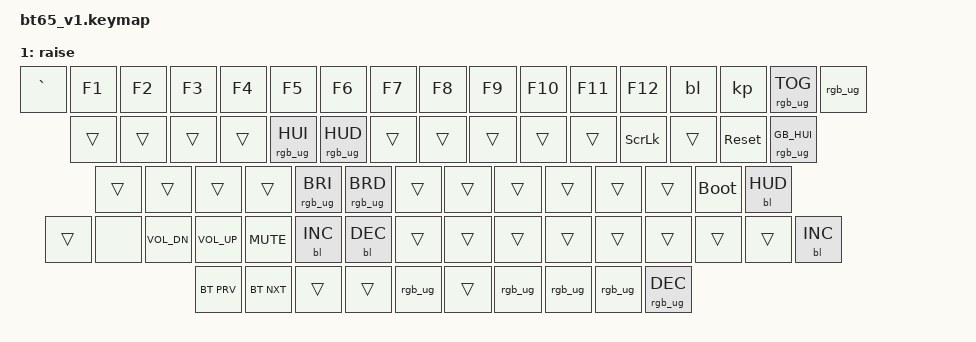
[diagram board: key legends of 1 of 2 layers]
#include <behaviors.dtsi>
#include <dt-bindings/zmk/keys.h>
#include <dt-bindings/zmk/bt.h>
#include <dt-bindings/zmk/rgb.h>
#include <dt-bindings/zmk/backlight.h>

#define ANSI
//#define ISO
//#define HHKB

/ {
  chosen {
  #ifdef ANSI
    zmk,matrix_transform = &ansi_transform;
  #elif defined(ISO)
    zmk,matrix_transform = &iso_transform;
  #elif defined(HHKB)
    zmk,matrix_transform = &hhkb_transform;
  #else
  #error "Layout not defined, please define a layout by uncommenting the appropriate line in bt65_v1.keymap"
  #endif
  };

  keymap {
    compatible = "zmk,keymap";
    #ifdef ANSI
    default_layer {
        // ------------------------------------------------------------------------------------------------
        // | ESC |  1  |  2  |  3  |  4  |  5  |  6  |  7  |  8  |  9  |  0  |  -  |  =  |   BKSP   | DEL |
        // | TAB   |  Q  |  W  |  E  |  R  |  T  |  Y  |  U  |  I  |  O  |  P  |  [  |  ]  |   \    | INS |
        // | CAPS   |  A  |  S  |  D  |  F  |  G  |  H  |  J  |  K  |  L  |  ;  |  '  |    ENTER    | PGUP|
        // |  SHIFT   |  Z  |  X  |  C  |  V  |  B  |  N  |  M  |  ,  |  .  |  /  |   SHIFT   | UP  | PGDN|
        // |  CTL  |  WIN  |  ALT  |             SPACE                | ALT |  1  |RCTRL| LEFT| DOWN|RIGHT|
        // ------------------------------------------------------------------------------------------------
      bindings = <

        &kp ESC &kp N1 &kp N2 &kp N3 &kp N4 &kp N5 &kp N6 &kp N7 &kp  N8   &kp  N9   &kp N0 &kp MINUS &kp EQUAL &kp BKSP &kp DEL
        &kp TAB   &kp Q  &kp W  &kp E  &kp R  &kp T  &kp Y  &kp U  &kp  I    &kp  O  &kp  P   &kp LBKT &kp RBKT &kp BSLH &kp INS
        &kp CLCK   &kp A  &kp S  &kp D  &kp F  &kp G  &kp H  &kp J  &kp  K    &kp  L  &kp SEMI &kp SQT         &kp RET &kp PG_UP
        &kp LSHFT     &kp Z  &kp X  &kp C  &kp V  &kp B  &kp N  &kp M  &kp COMMA &kp DOT &kp FSLH   &kp RSHFT   &kp UP &kp PG_DN
        &kp LCTRL &kp LGUI &kp LALT            &kp SPACE                   &kp RALT  &mo 1 &kp RCTRL &kp LEFT &kp DOWN &kp RIGHT
      >;
      sensor-bindings = <&inc_dec_kp C_VOL_UP C_VOL_DN>;
    };
    raise {
        // --------------------------------------------------------------------------------------------------
        // |GRAVE| F1  | F2  | F3  | F4  | F5  | F6  | F7  | F8  | F9  | F10 | F11 | F12 |PRSCRN|RGB_TOG|RGB_TOG|
        // | TAB  |  Q  |  W  |  E  | HUI | HUD |  Y  |  U  |  I  |  O  |  P  | SLCK|  ]  |  RESET   | RGB_HUI|
        // | CAPS  |  A  |  S  |  D  | BRI | BRD |  H  |  J  |  K  |  L  |  ;  |  '  |      BOOT     | RGB_HUD|
        // |SHIFT| NONE|VOLDN|VOLUP| MUTE|BLINC|BLDEC|  N  |  M  |  ,  |  .  |  /  |SHIFT| NONE|  UP | BL_INC|
        // | BT_PRV| BT_NXT|  ALT  |            SPACE                 | RGB_BRI |  1  | RGB_SPD| RGB_EFF| RGB_SAD |BL_DEC|
        // --------------------------------------------------------------------------------------------------
      bindings = <
        &kp GRAVE &kp F1 &kp F2 &kp F3 &kp F4 &kp F5 &kp F6 &kp F7 &kp F8 &kp F9 &kp F10 &kp F11 &kp F12 &bl &kp &rgb_ug RGB_TOG &rgb_ug
        &trans &trans &trans &trans &rgb_ug RGB_HUI &rgb_ug RGB_HUD &trans &trans &trans &trans &trans &kp SLCK &trans  &sys_reset  &rgb_ug GB_HUI
        &trans   &trans &trans &trans &rgb_ug RGB_BRI &rgb_ug RGB_BRD &trans &trans &trans &trans &trans  &trans  &bootloader &bl RGB_HUD
        &trans &none &kp C_VOL_DN &kp C_VOL_UP &kp C_MUTE &bl BL_INC &bl BL_DEC &trans &trans &trans &trans &trans &trans  &trans &trans &bl BL_INC
        &bt BT_PRV &bt BT_NXT  &trans              &trans                            &rgb_ug  &trans   &rgb_ug &rgb_ug &rgb_ug &rgb_ug BL_DEC
      >;
      sensor-bindings = <&inc_dec_kp C_VOL_UP C_VOL_DN>;
    };
    #elif defined(ISO)
    default_layer {
        // ------------------------------------------------------------------------------------------------
        // | ESC |  1  |  2  |  3  |  4  |  5  |  6  |  7  |  8  |  9  |  0  |  -  |  =  |   BKSP   | DEL |
        // | TAB   |  Q  |  W  |  E  |  R  |  T  |  Y  |  U  |  I  |  O  |  P  |  [  |  ]  |        | INS |
        // | CAPS   |  A  |  S  |  D  |  F  |  G  |  H  |  J  |  K  |  L  |  ;  |  '  |  #  | ENTER | PGUP|
        // |SHIFT |  \  |  Z  |  X  |  C  |  V  |  B  |  N  |  M  |  ,  |  .  |  /  |  SHIFT  | UP  | PGDN|
        // |  CTL  |  WIN  |  ALT  |             SPACE                | ALT |  1  |RCTRL| LEFT| DOWN|RIGHT|
        // ------------------------------------------------------------------------------------------------
      bindings = <

        &kp ESC &kp N1 &kp N2 &kp N3 &kp N4 &kp N5 &kp N6 &kp N7 &kp  N8   &kp  N9   &kp N0 &kp MINUS &kp EQUAL &kp BKSP &kp DEL
        &kp TAB   &kp Q  &kp W  &kp E  &kp R  &kp T  &kp Y  &kp U  &kp  I    &kp  O  &kp  P   &kp LBKT &kp RBKT          &kp INS
        &kp CLCK   &kp A  &kp S  &kp D  &kp F  &kp G  &kp H  &kp J  &kp  K    &kp  L  &kp SEMI &kp SQT &kp NON_US_HASH &kp RET &kp PG_UP
        &kp LSHFT &kp NON_US_BSLH &kp Z  &kp X  &kp C  &kp V  &kp B  &kp N  &kp M  &kp COMMA &kp DOT &kp FSLH   &kp RSHFT   &kp UP &kp PG_DN
        &kp LCTRL &kp LGUI &kp LALT            &kp SPACE                   &kp RALT  &mo 1 &kp RCTRL &kp LEFT &kp DOWN &kp RIGHT
      >;
      sensor-bindings = <&inc_dec_kp C_VOL_UP C_VOL_DN>;
    };
    raise {
        // --------------------------------------------------------------------------------------------------
        // |GRAVE| F1  | F2  | F3  | F4  | F5  | F6  | F7  | F8  | F9  | F10 | F11 | F12 |  BL_TOG  |RGB_TOG|
        // | TAB  |  Q  |  W  |  E  | HUI | HUD |  Y  |  U  |  I  |  O  |  P  | SLCK|  ]  |          | PSCRN|
        // | CAPS  |  A  |  S  |  D  | BRI | BRD |  H  |  J  |  K  |  L  |  ;  |  '  |RESET|   BOOT  | P_BRK|
        // |SHIFT |VOLDN|VOLUP| MUTE|BLINC|BLDEC|  B  |  N  |  M  |  ,  |  .  |  /  |  SHIFT  | HOME |  END |
        // | BT_PRV| BT_NXT|  ALT  |            SPACE               | ALT |  1  | CTRL | LEFT | DOWN |BT_CLR|
        // --------------------------------------------------------------------------------------------------
      bindings = <
        &kp GRAVE &kp F1 &kp F2 &kp F3 &kp F4 &kp F5 &kp F6 &kp F7 &kp F8 &kp F9 &kp F10 &kp F11 &kp F12 &bl BL_TOG &rgb_ug RGB_TOG
        &trans &trans &trans &trans &rgb_ug RGB_HUI &rgb_ug RGB_HUD &trans &trans &trans &trans &trans &kp SLCK &trans &kp PSCRN
        &trans   &trans &trans &trans &rgb_ug RGB_BRI &rgb_ug RGB_BRD &trans &trans &trans &trans &trans  &trans  &sys_reset  &bootloader &kp PAUSE_BREAK
        &trans &kp C_VOL_DN &kp C_VOL_UP &kp C_MUTE &bl BL_INC &bl BL_DEC  &trans &trans &trans &trans &trans &trans &trans  &kp HOME &kp END
        &bt BT_PRV &bt BT_NXT  &trans              &trans                            &trans   &trans   &trans &trans &trans  &bt BT_CLR
      >;
      sensor-bindings = <&inc_dec_kp C_VOL_UP C_VOL_DN>;
    };
    #elif defined(HHKB)
    default_layer {
        // ------------------------------------------------------------------------------------------------
        // | ESC |  1  |  2  |  3  |  4  |  5  |  6  |  7  |  8  |  9  |  0  |  -  |  =  |   BKSP   | DEL |
        // | TAB   |  Q  |  W  |  E  |  R  |  T  |  Y  |  U  |  I  |  O  |  P  |  [  |  ]  |   \    | HOME|
        // | CAPS   |  A  |  S  |  D  |  F  |  G  |  H  |  J  |  K  |  L  |  ;  |  '  |    ENTER    | END |
        // |  SHIFT   |  Z  |  X  |  C  |  V  |  B  |  N  |  M  |  ,  |  .  |  /  |      SHIFT      | PGUP|
        // |  CTL  |  WIN  |  ALT  |               SPACE                   |  ALT  |   1   |  CTRL  | PGDN|
        // ------------------------------------------------------------------------------------------------
      bindings = <

        &kp ESC &kp N1 &kp N2 &kp N3 &kp N4 &kp N5 &kp N6 &kp N7 &kp  N8   &kp  N9   &kp N0 &kp MINUS &kp EQUAL &kp BKSP &kp DEL
        &kp TAB   &kp Q  &kp W  &kp E  &kp R  &kp T  &kp Y  &kp U  &kp  I    &kp  O  &kp  P   &kp LBKT &kp RBKT &kp BSLH &kp HOME
        &kp CLCK   &kp A  &kp S  &kp D  &kp F  &kp G  &kp H  &kp J  &kp  K    &kp  L  &kp SEMI &kp SQT         &kp RET &kp END
        &kp LSHFT     &kp Z  &kp X  &kp C  &kp V  &kp B  &kp N  &kp M  &kp COMMA &kp DOT &kp FSLH   &kp RSHFT   &kp PG_UP
        &kp LCTRL &kp LGUI &kp LALT            &kp SPACE                   &kp RALT  &mo 1 &kp RCTRL  &kp PG_DN
      >;
      sensor-bindings = <&inc_dec_kp C_VOL_UP C_VOL_DN>;
    };
    raise {
        // --------------------------------------------------------------------------------------------------
        // |GRAVE| F1  | F2  | F3  | F4  | F5  | F6  | F7  | F8  | F9  | F10 | F11 | F12 |  BL_TOG  |RGB_TOG|
        // | TAB  |  Q  |  UP |  E  | HUI | HUD |  Y  |  U  |  I  |  O  |  P  | SLCK|  ]  |   RESET  | PSCRN|
        // | CAPS  | LEFT| DOWN|RIGHT| BRI | BRD |  H  |  J  |  K  |  L  |  ;  |  '  |      BOOT     | P_BRK|
        // |  SHIFT  |VOLDN|VOLUP| MUTE|BLINC|BLDEC|  N  |  M  |  ,  |  .  |  /  |      SHIFT        |  INS |
        // | BT_PRV | BT_NXT |  ALT   |             SPACE                   |  ALT  |   1   |  CTRL  |BT_CLR|
        // --------------------------------------------------------------------------------------------------
      bindings = <
        &kp GRAVE &kp F1 &kp F2 &kp F3 &kp F4 &kp F5 &kp F6 &kp F7 &kp F8 &kp F9 &kp F10 &kp F11 &kp F12 &bl BL_TOG &rgb_ug RGB_TOG
        &trans &trans &kp UP &trans &rgb_ug RGB_HUI &rgb_ug RGB_HUD &trans &trans &trans &trans &trans &kp SLCK &trans &sys_reset  &kp PSCRN
        &trans    &kp LEFT &kp DOWN &kp RIGHT  &rgb_ug RGB_BRI &rgb_ug RGB_BRD &trans &trans &trans &trans &trans  &trans  &bootloader &kp PAUSE_BREAK
        &trans  &kp C_VOL_DN &kp C_VOL_UP &kp C_MUTE &bl BL_INC &bl BL_DEC &trans &trans &trans &trans &trans  &trans  &kp INS
        &bt BT_PRV &bt BT_NXT  &trans              &trans                            &trans   &trans   &trans &bt BT_CLR
      >;
      sensor-bindings = <&inc_dec_kp C_VOL_UP C_VOL_DN>;
    };
    #else
    #error "Layout not defined, please define a layout by uncommenting the appropriate line in bt65_v1.keymap"
    #endif

  };
};
